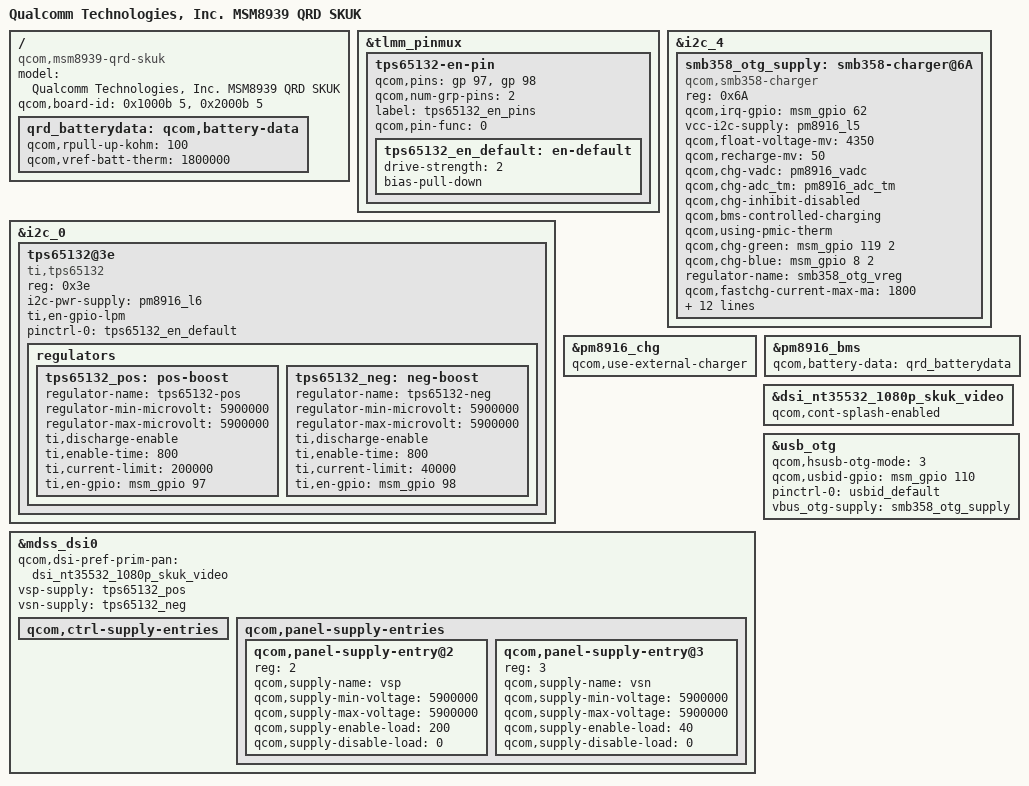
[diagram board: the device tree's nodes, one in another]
/* Copyright (c) 2014, 2020, The Linux Foundation. All rights reserved.
 *
 * This program is free software; you can redistribute it and/or modify
 * it under the terms of the GNU General Public License version 2 and
 * only version 2 as published by the Free Software Foundation.
 *
 * This program is distributed in the hope that it will be useful,
 * but WITHOUT ANY WARRANTY; without even the implied warranty of
 * MERCHANTABILITY or FITNESS FOR A PARTICULAR PURPOSE.  See the
 * GNU General Public License for more details.
 */

/dts-v1/;

#include "msm8939.dtsi"
#include "phab/phoenix/msm-pm8916-phoenix.dtsi"
#include "phab/phoenix/msm8939-common-phoenix.dtsi"
#include "phab/phoenix/msm8939-qrd-skuk-phoenix.dtsi"
#include "phab/phoenix/msm8939-qrd-phoenix.dtsi"
#include "phab/phoenix/dsi-panel-nt35532-1080p-skuk-video.dtsi"

/ {
	model = "Qualcomm Technologies, Inc. MSM8939 QRD SKUK";
	compatible = "qcom,msm8939-qrd-skuk", "qcom,msm8939-qrd", "qcom,msm8939", "qcom,qrd";
	qcom,board-id = <0x1000b 5>, <0x2000b 5>;
};

&tlmm_pinmux {
	tps65132-en-pin {
		qcom,pins = <&gp 97>, <&gp 98>;
		qcom,num-grp-pins = <2>;
		label = "tps65132_en_pins";
		qcom,pin-func = <0>;

		tps65132_en_default: en-default {
			drive-strength = <2>;
			bias-pull-down;
		};
	};
};

&i2c_0 { /* BLSP1 QUP2 */
	tps65132@3e {
		compatible = "ti,tps65132";
		reg = <0x3e>;
		i2c-pwr-supply = <&pm8916_l6>;
		ti,en-gpio-lpm;
		pinctrl-names = "default";
		pinctrl-0 = <&tps65132_en_default>;

		regulators {
			tps65132_pos: pos-boost {
				regulator-name = "tps65132-pos";
				regulator-min-microvolt = <5900000>;
				regulator-max-microvolt = <5900000>;
				ti,discharge-enable;
				ti,enable-time = <800>;
				ti,current-limit = <200000>;
				ti,en-gpio = <&msm_gpio 97 0>;
			};

			tps65132_neg: neg-boost {
				regulator-name = "tps65132-neg";
				regulator-min-microvolt = <5900000>;
				regulator-max-microvolt = <5900000>;
				ti,discharge-enable;
				ti,enable-time = <800>;
				ti,current-limit = <40000>;
				ti,en-gpio = <&msm_gpio 98 0>;
			};
		};
	};
};

&i2c_4 {
	smb358_otg_supply: smb358-charger@6A {
		compatible = "qcom,smb358-charger";
		reg = <0x6A>;
		qcom,irq-gpio = <&msm_gpio 62 2>;
		vcc-i2c-supply = <&pm8916_l5>;
		qcom,float-voltage-mv = <4350>;
		qcom,recharge-mv = <50>;
		qcom,chg-vadc = <&pm8916_vadc>;
		qcom,chg-adc_tm = <&pm8916_adc_tm>;
		qcom,chg-inhibit-disabled;
		qcom,bms-controlled-charging;
		qcom,using-pmic-therm;
		qcom,chg-green = <&msm_gpio 119 2>;
		qcom,chg-blue = <&msm_gpio 8 2>;
		regulator-name = "smb358_otg_vreg";
		qcom,fastchg-current-max-ma = <1800>;
		qcom,iterm-ma = <100>;
		qcom,iterm-disabled;
		qcom,bms-psy-name = "bms";
		qcom,hot-bat-decidegc = <500>;
		qcom,cold-bat-decidegc = <0>;
		qcom,bat-present-decidegc = <200>;
		qcom,warm-bat-decidegc = <450>;
		qcom,cool-bat-decidegc = <150>;
		qcom,warm-bat-ma = <1800>;
		qcom,cool-bat-ma = <720>;
		qcom,warm-bat-mv = <4100>;
		qcom,cool-bat-mv = <4350>;
	};
};

&pm8916_chg {
	status = "ok";
	qcom,use-external-charger;
};

/ {
	qrd_batterydata: qcom,battery-data {
		qcom,rpull-up-kohm = <100>;
		qcom,vref-batt-therm = <1800000>;

		#include "phab/phoenix/batterydata-qrd-skuk-scud-4v35-3600mah.dtsi"
		#include "phab/phoenix/batterydata-qrd-skuk-xwd-4v35-3500mah.dtsi"
	};
};

&pm8916_bms {
	status = "ok";
	qcom,battery-data = <&qrd_batterydata>;
};

&mdss_dsi0 {
	qcom,dsi-pref-prim-pan = <&dsi_nt35532_1080p_skuk_video>;

	/delete-property/ vdda-supply;
	/delete-property/ vdd-supply;

	vsp-supply = <&tps65132_pos>;
	vsn-supply = <&tps65132_neg>;

	qcom,ctrl-supply-entries {
		/delete-node/ qcom,ctrl-supply-entry@0;
	};

	qcom,panel-supply-entries {
		/delete-node/qcom,panel-supply-entry@0;

		qcom,panel-supply-entry@2 {
			reg = <2>;
			qcom,supply-name = "vsp";
			qcom,supply-min-voltage = <5900000>;
			qcom,supply-max-voltage = <5900000>;
			qcom,supply-enable-load = <200>;
			qcom,supply-disable-load = <0>;
		};

		qcom,panel-supply-entry@3 {
			reg = <3>;
			qcom,supply-name = "vsn";
			qcom,supply-min-voltage = <5900000>;
			qcom,supply-max-voltage = <5900000>;
			qcom,supply-enable-load = <40>;
			qcom,supply-disable-load = <0>;
		};
	};
};

&dsi_nt35532_1080p_skuk_video {
	qcom,cont-splash-enabled;
};

&usb_otg {
       qcom,hsusb-otg-mode = <3>;
       qcom,usbid-gpio = <&msm_gpio 110 0>;
       pinctrl-names = "default";
       pinctrl-0 = <&usbid_default>;
       vbus_otg-supply = <&smb358_otg_supply>;
};
